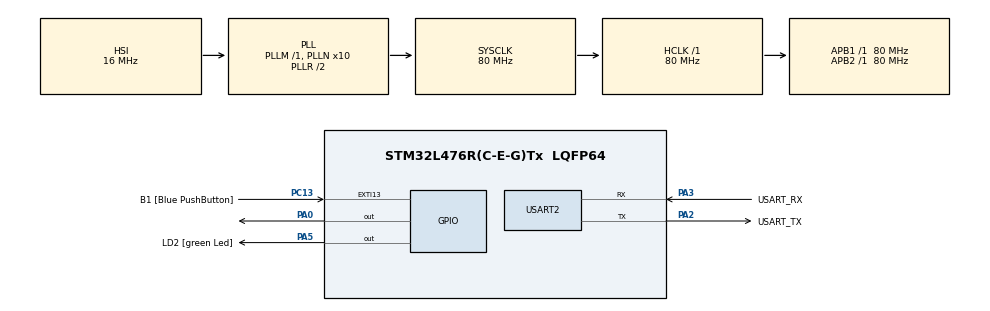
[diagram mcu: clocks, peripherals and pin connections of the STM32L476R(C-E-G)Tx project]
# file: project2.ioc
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FREERTOS.Tasks01=defaultTask,0,128,StartDefaultTask,Default,NULL,Dynamic,NULL,NULL
Mcu.Family=STM32L4
Mcu.Name=STM32L476R(C-E-G)Tx
Mcu.Package=LQFP64
NVIC.PriorityGroup=NVIC_PRIORITYGROUP_4
NVIC.TIM1_UP_TIM16_IRQn=true\:0\:0\:false\:false\:true\:false\:false\:true
NVIC.TimeBase=TIM1_UP_TIM16_IRQn
NVIC.TimeBaseIP=TIM1
PA0.Signal=GPIO_Output
PA13\ (JTMS-SWDIO).GPIO_Label=TMS
PA13\ (JTMS-SWDIO).Mode=Serial_Wire
PA13\ (JTMS-SWDIO).Signal=SYS_JTMS-SWDIO
PA14\ (JTCK-SWCLK).GPIO_Label=TCK
PA14\ (JTCK-SWCLK).Mode=Serial_Wire
PA14\ (JTCK-SWCLK).Signal=SYS_JTCK-SWCLK
PA2.GPIO_Label=USART_TX
PA2.GPIO_Mode=GPIO_MODE_AF_PP
PA2.GPIO_PuPd=GPIO_NOPULL
PA2.GPIO_Speed=GPIO_SPEED_FREQ_VERY_HIGH
PA2.Mode=Asynchronous
PA2.Signal=USART2_TX
PA3.GPIO_Label=USART_RX
PA3.GPIO_Mode=GPIO_MODE_AF_PP
PA3.GPIO_PuPd=GPIO_NOPULL
PA3.GPIO_Speed=GPIO_SPEED_FREQ_VERY_HIGH
PA3.Mode=Asynchronous
PA3.Signal=USART2_RX
PA5.GPIO_Label=LD2 [green Led]
PA5.GPIO_ModeDefaultOutputPP=GPIO_MODE_OUTPUT_PP
PA5.GPIO_PuPd=GPIO_NOPULL
PA5.GPIO_Speed=GPIO_SPEED_FREQ_LOW
PA5.PinState=GPIO_PIN_SET
PA5.Signal=GPIO_Output
PB3\ (JTDO-TRACESWO).GPIO_Label=SWO
PB3\ (JTDO-TRACESWO).Signal=SYS_JTDO-SWO
PC13.GPIO_Label=B1 [Blue PushButton]
PC13.GPIO_ModeDefaultEXTI=GPIO_MODE_IT_FALLING
PC13.GPIO_PuPd=GPIO_NOPULL
PC13.Signal=GPXTI13
PC14-OSC32_IN\ (PC14).Signal=RCC_OSC32_IN
PC15-OSC32_OUT\ (PC15).Signal=RCC_OSC32_OUT
PH0-OSC_IN\ (PH0).Mode=HSE-External-Oscillator
PH0-OSC_IN\ (PH0).Signal=RCC_OSC_IN
PH1-OSC_OUT\ (PH1).Mode=HSE-External-Oscillator
PH1-OSC_OUT\ (PH1).Signal=RCC_OSC_OUT
ProjectManager.HeapSize=0x200
ProjectManager.StackSize=0x400
ProjectManager.TargetToolchain=STM32CubeIDE
RCC.ADCFreq_Value=32000000
RCC.AHBFreq_Value=80000000
RCC.APB1Freq_Value=80000000
RCC.APB1TimFreq_Value=80000000
RCC.APB2Freq_Value=80000000
RCC.APB2TimFreq_Value=80000000
RCC.CortexFreq_Value=80000000
RCC.HCLKFreq_Value=80000000
RCC.HSE_VALUE=8000000
RCC.HSI_VALUE=16000000
RCC.MSI_VALUE=4000000
RCC.PLLN=20
RCC.PLLSourceVirtual=RCC_PLLSOURCE_HSE
RCC.PREFETCH_ENABLE=1
RCC.SYSCLKFreq_VALUE=80000000
RCC.SYSCLKSource=RCC_SYSCLKSOURCE_PLLCLK
RCC.USBFreq_Value=32000000
RCC.VCOOutputFreq_Value=160000000
TIM2.Period=0xffff-1
TIM2.Prescaler=1-1
USART2.VirtualMode-Asynchronous=VM_ASYNC
VP_FREERTOS_VS_CMSIS_V1.Mode=CMSIS_V1
VP_SYS_VS_tim1.Mode=TIM1
VP_TIM2_VS_ClockSourceINT.Mode=Internal
board=NUCLEO-L476RG

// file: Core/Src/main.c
/* USER CODE BEGIN Header */
/**
  ******************************************************************************
  * @file           : main.c
  * @brief          : Main program body
  ******************************************************************************
  * @attention
  *
  * <h2><center>&copy; Copyright (c) 2021 STMicroelectronics.
  * All rights reserved.</center></h2>
  *
  * This software component is licensed by ST under BSD 3-Clause license,
  * the "License"; You may not use this file except in compliance with the
  * License. You may obtain a copy of the License at:
  *                        opensource.org/licenses/BSD-3-Clause
  *
  ******************************************************************************
  */
/* USER CODE END Header */
#include "main.h"
#include "cmsis_os.h"
#include "tim.h"
#include "usart.h"
#include "gpio.h"

void SystemClock_Config(void);
void MX_FREERTOS_Init(void);

int main(void)
{

  /* MCU Configuration--------------------------------------------------------*/

  /* Reset of all peripherals, Initializes the Flash interface and the Systick. */
  HAL_Init();

  /* Configure the system clock */
  SystemClock_Config();

  /* Initialize all configured peripherals */
  MX_GPIO_Init();
  MX_USART2_UART_Init();
  MX_TIM2_Init();
  /* USER CODE BEGIN 2 */
  HAL_TIM_Base_Start(&htim2);
  /* USER CODE END 2 */

  /* Call init function for freertos objects (in freertos.c) */
  MX_FREERTOS_Init();
  /* Start scheduler */
  osKernelStart();

  /* We should never get here as control is now taken by the scheduler */
  /* Infinite loop */
  while (1)
  {
  }
}

void SystemClock_Config(void)
{
  RCC_OscInitTypeDef RCC_OscInitStruct = {0};
  RCC_ClkInitTypeDef RCC_ClkInitStruct = {0};
  RCC_PeriphCLKInitTypeDef PeriphClkInit = {0};

  /** Initializes the RCC Oscillators according to the specified parameters
  * in the RCC_OscInitTypeDef structure.
  */
  RCC_OscInitStruct.OscillatorType = RCC_OSCILLATORTYPE_HSI;
  RCC_OscInitStruct.HSIState = RCC_HSI_ON;
  RCC_OscInitStruct.HSICalibrationValue = RCC_HSICALIBRATION_DEFAULT;
  RCC_OscInitStruct.PLL.PLLState = RCC_PLL_ON;
  RCC_OscInitStruct.PLL.PLLSource = RCC_PLLSOURCE_HSI;
  RCC_OscInitStruct.PLL.PLLM = 1;
  RCC_OscInitStruct.PLL.PLLN = 10;
  RCC_OscInitStruct.PLL.PLLP = RCC_PLLP_DIV7;
  RCC_OscInitStruct.PLL.PLLQ = RCC_PLLQ_DIV2;
  RCC_OscInitStruct.PLL.PLLR = RCC_PLLR_DIV2;
  if (HAL_RCC_OscConfig(&RCC_OscInitStruct) != HAL_OK)
  {
    Error_Handler();
  }
  /** Initializes the CPU, AHB and APB buses clocks
  */
  RCC_ClkInitStruct.ClockType = RCC_CLOCKTYPE_HCLK|RCC_CLOCKTYPE_SYSCLK
                              |RCC_CLOCKTYPE_PCLK1|RCC_CLOCKTYPE_PCLK2;
  RCC_ClkInitStruct.SYSCLKSource = RCC_SYSCLKSOURCE_PLLCLK;
  RCC_ClkInitStruct.AHBCLKDivider = RCC_SYSCLK_DIV1;
  RCC_ClkInitStruct.APB1CLKDivider = RCC_HCLK_DIV1;
  RCC_ClkInitStruct.APB2CLKDivider = RCC_HCLK_DIV1;

  if (HAL_RCC_ClockConfig(&RCC_ClkInitStruct, FLASH_LATENCY_4) != HAL_OK)
  {
    Error_Handler();
  }
  PeriphClkInit.PeriphClockSelection = RCC_PERIPHCLK_USART2;
  PeriphClkInit.Usart2ClockSelection = RCC_USART2CLKSOURCE_PCLK1;
  if (HAL_RCCEx_PeriphCLKConfig(&PeriphClkInit) != HAL_OK)
  {
    Error_Handler();
  }
  /** Configure the main internal regulator output voltage
  */
  if (HAL_PWREx_ControlVoltageScaling(PWR_REGULATOR_VOLTAGE_SCALE1) != HAL_OK)
  {
    Error_Handler();
  }
}

 /**
  * @brief  Period elapsed callback in non blocking mode
  * @note   This function is called  when TIM1 interrupt took place, inside
  * HAL_TIM_IRQHandler(). It makes a direct call to HAL_IncTick() to increment
  * a global variable "uwTick" used as application time base.
  * @param  htim : TIM handle
  * @retval None
  */
void HAL_TIM_PeriodElapsedCallback(TIM_HandleTypeDef *htim)
{
  if (htim->Instance == TIM1) {
    HAL_IncTick();
  }
}

void Error_Handler(void)
{
  __disable_irq();
  while (1)
  {
  }
}

/************************ (C) COPYRIGHT STMicroelectronics *****END OF FILE****/

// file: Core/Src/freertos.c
/* USER CODE BEGIN Header */
/**
  ******************************************************************************
  * File Name          : freertos.c
  * Description        : Code for freertos applications
  ******************************************************************************
  * @attention
  *
  * <h2><center>&copy; Copyright (c) 2021 STMicroelectronics.
  * All rights reserved.</center></h2>
  *
  * This software component is licensed by ST under Ultimate Liberty license
  * SLA0044, the "License"; You may not use this file except in compliance with
  * the License. You may obtain a copy of the License at:
  *                             www.st.com/SLA0044
  *
  ******************************************************************************
  */
/* USER CODE END Header */

#include "FreeRTOS.h"
#include "task.h"
#include "main.h"
#include "cmsis_os.h"
#include "DHT11.h"

/* USER CODE BEGIN Includes */
#include "usart.h"
/* USER CODE END Includes */

/* USER CODE BEGIN Variables */
uint8_t temperature = 0;
uint8_t humidity = 0;
/* USER CODE END Variables */
osThreadId defaultTaskHandle;

void StartDefaultTask(void const * argument);

void MX_FREERTOS_Init(void); /* (MISRA C 2004 rule 8.1) */

/* GetIdleTaskMemory prototype (linked to static allocation support) */
void vApplicationGetIdleTaskMemory( StaticTask_t **ppxIdleTaskTCBBuffer, StackType_t **ppxIdleTaskStackBuffer, uint32_t *pulIdleTaskStackSize );

/* USER CODE BEGIN GET_IDLE_TASK_MEMORY */
static StaticTask_t xIdleTaskTCBBuffer;
static StackType_t xIdleStack[configMINIMAL_STACK_SIZE];

void vApplicationGetIdleTaskMemory( StaticTask_t **ppxIdleTaskTCBBuffer, StackType_t **ppxIdleTaskStackBuffer, uint32_t *pulIdleTaskStackSize )
{
  *ppxIdleTaskTCBBuffer = &xIdleTaskTCBBuffer;
  *ppxIdleTaskStackBuffer = &xIdleStack[0];
  *pulIdleTaskStackSize = configMINIMAL_STACK_SIZE;
  /* place for user code */
}
/* USER CODE END GET_IDLE_TASK_MEMORY */

void MX_FREERTOS_Init(void) {

  /* Create the thread(s) */
  /* definition and creation of defaultTask */
  osThreadDef(defaultTask, StartDefaultTask, osPriorityNormal, 0, 128);
  defaultTaskHandle = osThreadCreate(osThread(defaultTask), NULL);

}

void StartDefaultTask(void const * argument)
{
  /* USER CODE BEGIN StartDefaultTask */
  /* Infinite loop */
	for(;;)
	{
		DHT11_Receive_Data(&humidity, &temperature);
		HAL_Delay(2000);
//		static char data[20];
//		sprintf((char *)data, "-%i-%i\r\n", humidity, temperature);
//		HAL_UART_Transmit(&huart2, data, sizeof(data), 100);
	}
  /* USER CODE END StartDefaultTask */
}

/************************ (C) COPYRIGHT STMicroelectronics *****END OF FILE****/
